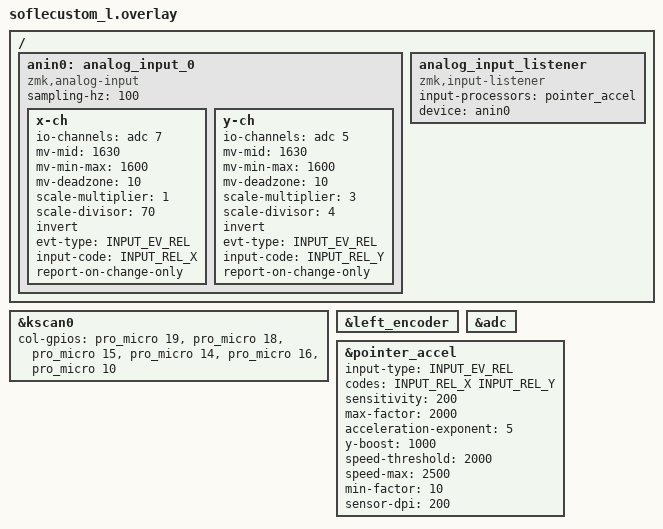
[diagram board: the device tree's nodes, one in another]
/*
 * Copyright (c) 2020 Ryan Cross
 *
 * SPDX-License-Identifier: MIT
 */

#include "soflecustom.dtsi"
#include <dt-bindings/zmk/matrix_transform.h>
#include <zephyr/dt-bindings/input/input-event-codes.h>
#include <input/processors.dtsi>
#include <dt-bindings/zmk/input_transform.h>
#include <zephyr/dt-bindings/input/input-event-codes.h>
#include <behaviors/input_gestures_accel.dtsi>

&kscan0 {
    col-gpios
        = <&pro_micro 19 GPIO_ACTIVE_HIGH>
        , <&pro_micro 18 GPIO_ACTIVE_HIGH>
        , <&pro_micro 15 GPIO_ACTIVE_HIGH>
        , <&pro_micro 14 GPIO_ACTIVE_HIGH>
        , <&pro_micro 16 GPIO_ACTIVE_HIGH>
        , <&pro_micro 10 GPIO_ACTIVE_HIGH>
        ;
};

&left_encoder {
    status = "okay";
};

/* Reference: https://docs.zephyrproject.org/apidoc/latest/group__input__events.html */

&adc {
	status = "okay";
};

&pointer_accel {
	input-type = <INPUT_EV_REL>;
	codes = <INPUT_REL_X INPUT_REL_Y>;
	sensitivity = <200>;         // 1.2x base sensitivity
	max-factor = <2000>;          // 3.0x maximum acceleration
	acceleration-exponent = <5>;  // Advanced exponential curve (1-5)
	y-boost = <1000>;             // 1.3x Y-axis boost for widescreen
	speed-threshold = <2000>;      // Start acceleration at 600 counts/sec
	speed-max = <2500>;           // Max acceleration at 3500 counts/sec
	min-factor = <10>;          // 1.0x minimum (no deceleration)
	sensor-dpi = <200>;           // 800 DPI sensor (optional, defaults to 800)
};

/ {
	anin0: analog_input_0 {
		compatible = "zmk,analog-input";
		sampling-hz = <100>;
		x-ch {
			io-channels = <&adc 7>; // <--- see ain-map.png for nRF52840
			mv-mid = <1630>;
			mv-min-max = <1600>;
			mv-deadzone = <10>;
			scale-multiplier = <1>;
			scale-divisor = <70>;
			invert;
			evt-type = <INPUT_EV_REL>;
			input-code = <INPUT_REL_X>;

            report-on-change-only;
		};

		y-ch {
			io-channels = <&adc 5>; // <--- see ain-map.png for nRF52840
			mv-mid = <1630>;
			mv-min-max = <1600>;
			mv-deadzone = <10>;
			scale-multiplier = <3>;
			scale-divisor = <4>;
			invert;
			evt-type = <INPUT_EV_REL>;
			input-code = <INPUT_REL_Y>;

			/* enable report mdoe for gamepad axix or knob */
			/* to only call input_report on quantquantized value is updated */
			/* NOTE: mouse input does NOT need this */
			report-on-change-only;

		};
	};

	analog_input_listener {
        status = "okay";
		input-processors = <&pointer_accel>;
        compatible = "zmk,input-listener";
        device = <&anin0>;
    };
};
